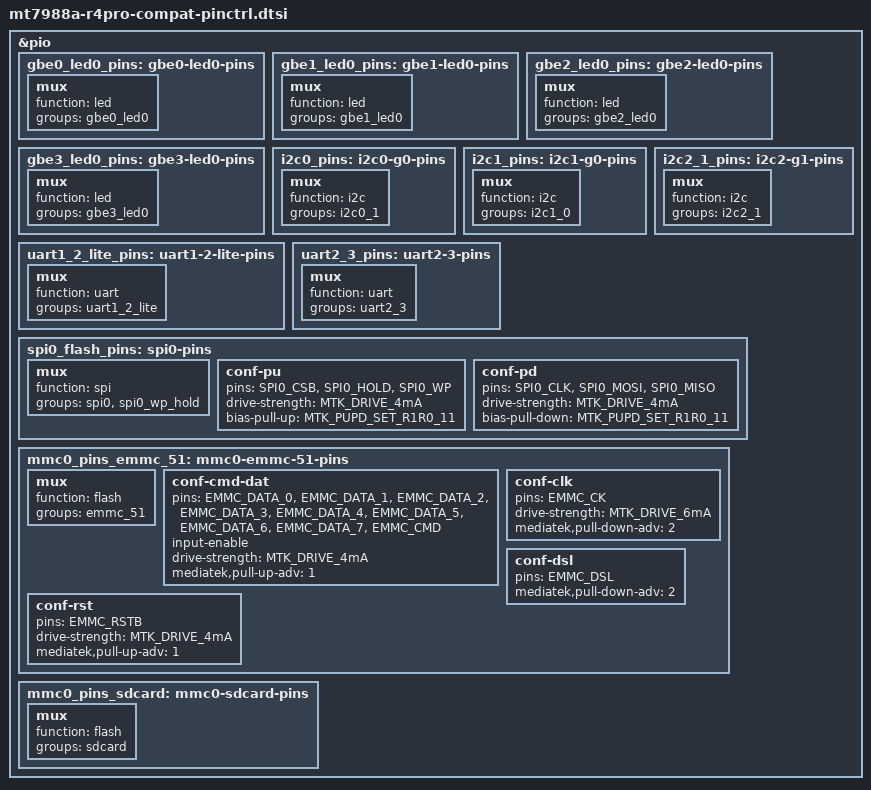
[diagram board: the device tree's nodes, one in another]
// SPDX-License-Identifier: (GPL-2.0 OR MIT)
/* Compatibility pin groups required by the BPI-R4 Pro 8X board DTS.
 * Extracted from the MediaTek MT7988 pinctrl board definitions. The R4 Pro
 * includes mt7988a.dtsi directly, where these board-level groups are absent.
 */
#include <dt-bindings/gpio/gpio.h>

&pio {
	gbe0_led0_pins: gbe0-led0-pins {
		mux {
			function = "led";
			groups = "gbe0_led0";
		};
	};

	gbe1_led0_pins: gbe1-led0-pins {
		mux {
			function = "led";
			groups = "gbe1_led0";
		};
	};

	gbe2_led0_pins: gbe2-led0-pins {
		mux {
			function = "led";
			groups = "gbe2_led0";
		};
	};

	gbe3_led0_pins: gbe3-led0-pins {
		mux {
			function = "led";
			groups = "gbe3_led0";
		};
	};

	i2c0_pins: i2c0-g0-pins {
		mux {
			function = "i2c";
			groups = "i2c0_1";
		};
	};

	i2c1_pins: i2c1-g0-pins {
		mux {
			function = "i2c";
			groups = "i2c1_0";
		};
	};

	i2c2_1_pins: i2c2-g1-pins {
		mux {
			function = "i2c";
			groups = "i2c2_1";
		};
	};

	uart1_2_lite_pins: uart1-2-lite-pins {
		mux {
			function = "uart";
			groups =  "uart1_2_lite";
		};
	};

	uart2_3_pins: uart2-3-pins {
		mux {
			function = "uart";
			groups =  "uart2_3";
		};
	};

	spi0_flash_pins: spi0-pins {
		mux {
			function = "spi";
			groups = "spi0", "spi0_wp_hold";
		};

		conf-pu {
			pins = "SPI0_CSB", "SPI0_HOLD", "SPI0_WP";
			drive-strength = <MTK_DRIVE_4mA>;
			bias-pull-up = <MTK_PUPD_SET_R1R0_11>;
		};

		conf-pd {
			pins = "SPI0_CLK", "SPI0_MOSI", "SPI0_MISO";
			drive-strength = <MTK_DRIVE_4mA>;
			bias-pull-down = <MTK_PUPD_SET_R1R0_11>;
		};
	};

	mmc0_pins_emmc_51: mmc0-emmc-51-pins {
		mux {
			function = "flash";
			groups = "emmc_51";
		};

		conf-cmd-dat {
			pins = "EMMC_DATA_0", "EMMC_DATA_1", "EMMC_DATA_2",
			       "EMMC_DATA_3", "EMMC_DATA_4", "EMMC_DATA_5",
			       "EMMC_DATA_6", "EMMC_DATA_7", "EMMC_CMD";
			input-enable;
			drive-strength = <MTK_DRIVE_4mA>;
			mediatek,pull-up-adv = <1>;	/* pull-up 10K */
		};

		conf-clk {
			pins = "EMMC_CK";
			drive-strength = <MTK_DRIVE_6mA>;
			mediatek,pull-down-adv = <2>;	/* pull-down 50K */
		};

		conf-dsl {
			pins = "EMMC_DSL";
			mediatek,pull-down-adv = <2>;	/* pull-down 50K */
		};

		conf-rst {
			pins = "EMMC_RSTB";
			drive-strength = <MTK_DRIVE_4mA>;
			mediatek,pull-up-adv = <1>;	/* pull-up 10K */
		};
	};

	mmc0_pins_sdcard: mmc0-sdcard-pins {
		mux {
			function = "flash";
			groups = "sdcard";
		};
	};
};
